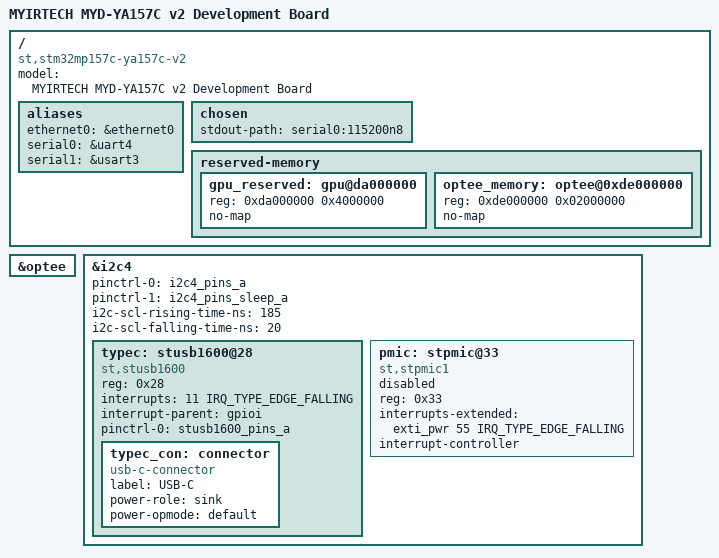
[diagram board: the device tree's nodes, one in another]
// SPDX-License-Identifier: (GPL-2.0+ OR BSD-3-Clause)
/*
 * Copyright (C) STMicroelectronics 2018 - All Rights Reserved
 * Author: Alexandre Torgue <alexandre.torgue@st.com>.
 */

/dts-v1/;

#include "stm32mp157.dtsi"
#include "stm32mp15xa.dtsi"
#include "stm32mp157-pinctrl.dtsi"
#include "stm32mp15xxac-pinctrl.dtsi"
#include "stm32mp15xx-ya157c.dtsi"

/ {
	model = "MYIRTECH MYD-YA157C v2 Development Board";
	compatible = "st,stm32mp157c-ya157c-v2", "st,stm32mp157";

	aliases {
		ethernet0 = &ethernet0;
		serial0 = &uart4;
		serial1 = &usart3;
		//serial2 = &uart7;
	};

	chosen {
		stdout-path = "serial0:115200n8";
	};

	reserved-memory {
		gpu_reserved: gpu@da000000 {
			reg = <0xda000000 0x4000000>;
			no-map;
		};

		optee_memory: optee@0xde000000 {
			reg = <0xde000000 0x02000000>;
			no-map;
		};
	};
	
};

&optee {
	status = "okay";
};

&i2c4 {
	pinctrl-names = "default", "sleep";
	pinctrl-0 = <&i2c4_pins_a>;
	pinctrl-1 = <&i2c4_pins_sleep_a>;
	i2c-scl-rising-time-ns = <185>;
	i2c-scl-falling-time-ns = <20>;
	status = "okay";
	/delete-property/dmas;
	/delete-property/dma-names;

	typec: stusb1600@28 {
		compatible = "st,stusb1600";
		reg = <0x28>;
		interrupts = <11 IRQ_TYPE_EDGE_FALLING>;
		interrupt-parent = <&gpioi>;
		pinctrl-names = "default";
		pinctrl-0 = <&stusb1600_pins_a>;

		status = "okay";

		typec_con: connector {
			compatible = "usb-c-connector";
			label = "USB-C";
			power-role = "sink";
			power-opmode = "default";
		};
	};

	pmic: stpmic@33 {
		compatible = "st,stpmic1";
		reg = <0x33>;
		interrupts-extended = <&exti_pwr 55 IRQ_TYPE_EDGE_FALLING>;
		interrupt-controller;
		#interrupt-cells = <2>;
		status = "disable";

	};
};




